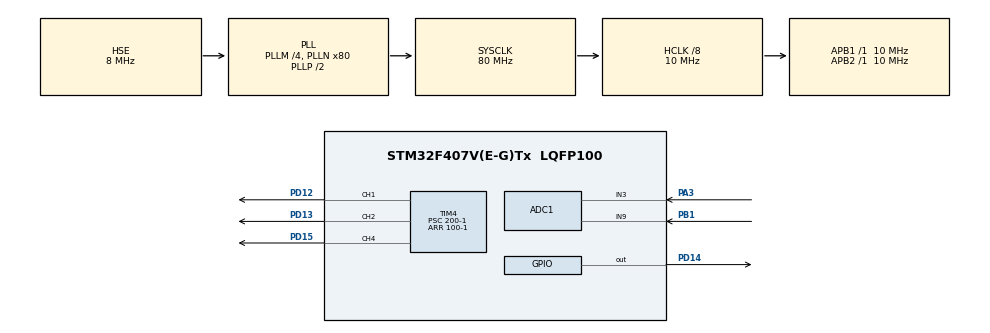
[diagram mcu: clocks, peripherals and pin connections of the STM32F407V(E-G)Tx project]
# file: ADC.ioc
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ADC1.Channel-4\#ChannelRegularConversion=ADC_CHANNEL_TEMPSENSOR
ADC1.Channel-5\#ChannelRegularConversion=ADC_CHANNEL_3
ADC1.Channel-6\#ChannelRegularConversion=ADC_CHANNEL_9
ADC1.ContinuousConvMode=DISABLE
ADC1.NbrOfConversion=3
ADC1.NbrOfConversionFlag=1
ADC1.Rank-4\#ChannelRegularConversion=1
ADC1.Rank-5\#ChannelRegularConversion=2
ADC1.Rank-6\#ChannelRegularConversion=3
ADC1.SamplingTime-4\#ChannelRegularConversion=ADC_SAMPLETIME_480CYCLES
ADC1.SamplingTime-5\#ChannelRegularConversion=ADC_SAMPLETIME_480CYCLES
ADC1.SamplingTime-6\#ChannelRegularConversion=ADC_SAMPLETIME_480CYCLES
ADC1.ScanConvMode=ENABLE
ADC1.master=1
Dma.ADC1.0.Direction=DMA_PERIPH_TO_MEMORY
Dma.ADC1.0.FIFOMode=DMA_FIFOMODE_DISABLE
Dma.ADC1.0.Instance=DMA2_Stream0
Dma.ADC1.0.MemDataAlignment=DMA_MDATAALIGN_WORD
Dma.ADC1.0.MemInc=DMA_MINC_ENABLE
Dma.ADC1.0.Mode=DMA_NORMAL
Dma.ADC1.0.PeriphDataAlignment=DMA_PDATAALIGN_WORD
Dma.ADC1.0.PeriphInc=DMA_PINC_DISABLE
Dma.ADC1.0.Priority=DMA_PRIORITY_LOW
Dma.Request0=ADC1
Mcu.Family=STM32F4
Mcu.Name=STM32F407V(E-G)Tx
Mcu.Package=LQFP100
NVIC.DMA2_Stream0_IRQn=true\:0\:0\:false\:false\:true\:false\:true
NVIC.PriorityGroup=NVIC_PRIORITYGROUP_4
NVIC.TIM3_IRQn=true\:0\:0\:false\:false\:true\:true\:true
NVIC.TIM4_IRQn=true\:0\:0\:false\:false\:true\:true\:true
PA3.Signal=ADCx_IN3
PB1.Signal=ADCx_IN9
PD12.Signal=S_TIM4_CH1
PD13.Signal=S_TIM4_CH2
PD14.Signal=GPIO_Output
PD15.Signal=S_TIM4_CH4
PH0-OSC_IN.Mode=HSE-External-Oscillator
PH0-OSC_IN.Signal=RCC_OSC_IN
PH1-OSC_OUT.Mode=HSE-External-Oscillator
PH1-OSC_OUT.Signal=RCC_OSC_OUT
ProjectManager.HeapSize=0x200
ProjectManager.StackSize=0x400
ProjectManager.TargetToolchain=STM32CubeIDE
RCC.48MHZClocksFreq_Value=40000000
RCC.AHBCLKDivider=RCC_SYSCLK_DIV8
RCC.AHBFreq_Value=10000000
RCC.APB1Freq_Value=10000000
RCC.APB1TimFreq_Value=10000000
RCC.APB2Freq_Value=10000000
RCC.APB2TimFreq_Value=10000000
RCC.CortexFreq_Value=10000000
RCC.HCLKFreq_Value=10000000
RCC.HSE_VALUE=8000000
RCC.HSI_VALUE=16000000
RCC.LSE_VALUE=32768
RCC.PLLM=4
RCC.PLLN=80
RCC.PLLSourceVirtual=RCC_PLLSOURCE_HSE
RCC.SYSCLKFreq_VALUE=80000000
RCC.SYSCLKSource=RCC_SYSCLKSOURCE_PLLCLK
RCC.VCOOutputFreq_Value=160000000
SH.ADCx_IN3.0=ADC1_IN3,IN3
SH.ADCx_IN9.0=ADC1_IN9,IN9
SH.S_TIM4_CH1.0=TIM4_CH1,PWM Generation1 CH1
SH.S_TIM4_CH2.0=TIM4_CH2,PWM Generation2 CH2
SH.S_TIM4_CH4.0=TIM4_CH4,PWM Generation4 CH4
TIM3.Period=0
TIM3.Prescaler=10000-1
TIM4.Channel-PWM\ Generation1\ CH1=TIM_CHANNEL_1
TIM4.Channel-PWM\ Generation2\ CH2=TIM_CHANNEL_2
TIM4.Channel-PWM\ Generation4\ CH4=TIM_CHANNEL_4
TIM4.Period=100-1
TIM4.Prescaler=200-1
TIM4.TIM_MasterOutputTrigger=TIM_TRGO_UPDATE
TIM4.TIM_MasterSlaveMode=TIM_MASTERSLAVEMODE_ENABLE
VP_ADC1_TempSens_Input.Mode=IN-TempSens
VP_TIM3_VS_ClockSourceINT.Mode=Internal
VP_TIM4_VS_ClockSourceINT.Mode=Internal
board=custom

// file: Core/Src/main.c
/* USER CODE BEGIN Header */
/**
  ******************************************************************************
  * @file           : main.c
  * @brief          : Main program body
  ******************************************************************************
  * @attention
  *
  * <h2><center>&copy; Copyright (c) 2021 STMicroelectronics.
  * All rights reserved.</center></h2>
  *
  * This software component is licensed by ST under BSD 3-Clause license,
  * the "License"; You may not use this file except in compliance with the
  * License. You may obtain a copy of the License at:
  *                        opensource.org/licenses/BSD-3-Clause
  *
  ******************************************************************************
  */
/* USER CODE END Header */
#include "main.h"
#include "adc.h"
#include "dma.h"
#include "tim.h"
#include "gpio.h"

void SystemClock_Config(void);

int main(void)
{

  /* MCU Configuration--------------------------------------------------------*/

  /* Reset of all peripherals, Initializes the Flash interface and the Systick. */
  HAL_Init();

  /* Configure the system clock */
  SystemClock_Config();

  /* Initialize all configured peripherals */
  MX_GPIO_Init();
  MX_TIM4_Init();
  MX_DMA_Init();
  MX_ADC1_Init();
  MX_TIM3_Init();
  /* USER CODE BEGIN 2 */
  HAL_TIM_Base_Start_IT(&htim3);																	//Start TIM3 with interrupts
  TIM3->CR1 |= TIM_CR1_UDIS;																		//Dissable update interrupt
  HAL_TIM_Base_Start_IT(&htim4);																	//Start TIM3 with interrupts
  HAL_TIM_PWM_Start(&htim4, TIM_CHANNEL_1);															//Enable PWM on channel 1 of TIM4
  HAL_TIM_PWM_Start(&htim4, TIM_CHANNEL_2);															//Enable PWM on channel 2 of TIM4
  HAL_TIM_PWM_Start(&htim4, TIM_CHANNEL_4);															//Enable PWM on channel 4 of TIM4
  /* USER CODE END 2 */

  /* Infinite loop */
  while (1)
  {

  }
}

void SystemClock_Config(void)
{
  RCC_OscInitTypeDef RCC_OscInitStruct = {0};
  RCC_ClkInitTypeDef RCC_ClkInitStruct = {0};

  /** Configure the main internal regulator output voltage
  */
  __HAL_RCC_PWR_CLK_ENABLE();
  __HAL_PWR_VOLTAGESCALING_CONFIG(PWR_REGULATOR_VOLTAGE_SCALE1);
  /** Initializes the RCC Oscillators according to the specified parameters
  * in the RCC_OscInitTypeDef structure.
  */
  RCC_OscInitStruct.OscillatorType = RCC_OSCILLATORTYPE_HSE;
  RCC_OscInitStruct.HSEState = RCC_HSE_ON;
  RCC_OscInitStruct.PLL.PLLState = RCC_PLL_ON;
  RCC_OscInitStruct.PLL.PLLSource = RCC_PLLSOURCE_HSE;
  RCC_OscInitStruct.PLL.PLLM = 4;
  RCC_OscInitStruct.PLL.PLLN = 80;
  RCC_OscInitStruct.PLL.PLLP = RCC_PLLP_DIV2;
  RCC_OscInitStruct.PLL.PLLQ = 4;
  if (HAL_RCC_OscConfig(&RCC_OscInitStruct) != HAL_OK)
  {
    Error_Handler();
  }
  /** Initializes the CPU, AHB and APB buses clocks
  */
  RCC_ClkInitStruct.ClockType = RCC_CLOCKTYPE_HCLK|RCC_CLOCKTYPE_SYSCLK
                              |RCC_CLOCKTYPE_PCLK1|RCC_CLOCKTYPE_PCLK2;
  RCC_ClkInitStruct.SYSCLKSource = RCC_SYSCLKSOURCE_PLLCLK;
  RCC_ClkInitStruct.AHBCLKDivider = RCC_SYSCLK_DIV8;
  RCC_ClkInitStruct.APB1CLKDivider = RCC_HCLK_DIV1;
  RCC_ClkInitStruct.APB2CLKDivider = RCC_HCLK_DIV1;

  if (HAL_RCC_ClockConfig(&RCC_ClkInitStruct, FLASH_LATENCY_0) != HAL_OK)
  {
    Error_Handler();
  }
}

void Error_Handler(void)
{
  __disable_irq();
  while (1)
  {
  }
}

/************************ (C) COPYRIGHT STMicroelectronics *****END OF FILE****/
